# STM32L4x5 register map
File version: 1.8
CPU: CM4 r0p1, little endian, MPU, FPU, 4 interrupt priority bits
Registers are 32-bit, read-write, reset 0x0 unless marked. A register's access mark holds for its fields unless they carry their own. Offsets are from the block's base; [hi:lo] are bit positions; {n}, {i} and the like mark numbered series.

## AES — Advanced encryption standard hardware accelerator
Base 0x50060000
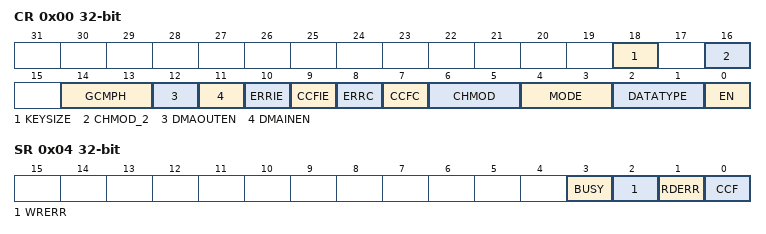
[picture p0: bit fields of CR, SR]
0x00 CR — control register
  [18] KEYSIZE — Key size selection
    0=AES128 (128); 1=AES256 (256)
  [16] CHMOD_2 — Chaining mode selection, bit [2]
    0=CHMOD (Mode as per CHMOD (ECB, CBC, CTR, GCM)); 1=CCM (Counter with CBC-MAC (CCM) - CHMOD must be 0 (ECB))
  [14:13] GCMPH — GCM or CCM phase selection
    0=Init phase; 1=Header phase; 2=Payload phase; 3=Final Phase
  [12] DMAOUTEN — Enable DMA management of data output phase
    0=Disable DMA Output; 1=Enabled DMA Output
  [11] DMAINEN — Enable DMA management of data input phase
    0=Disable DMA Input; 1=Enable DMA Input
  [10] ERRIE — Error interrupt enable
    0=Disabled (Disable (mask) error interrupt); 1=Enabled (Enable error interrupt)
  [9] CCFIE — CCF flag interrupt enable
    0=Disabled (Disable (mask) CCF interrupt); 1=Enabled (Enable CCF interrupt)
  [8] ERRC — Error clear
    on write: 1=Clear RDERR and WRERR flags
  [7] CCFC — Computation Complete Flag Clear
    on write: 1=Clear computation complete flag
  [6:5] CHMOD — AES chaining mode
    0=ECB (Electronic codebook (ECB) / Counter with CBC-MAC (CCM) if CHMOD2 is 1); 1=CBC (Cipher-block chaining (CBC)); 2=CTR (Counter mode (CTR)); 3=GCM (Galois counter mode (GCM) and Galois message authentication code (GMAC))
  [4:3] MODE — AES operating mode
    0=Mode 1: encryption; 1=Mode 2: key derivation (or key preparation for ECB/CBC decryption); 2=Mode 3: decryption; 3=Mode 4: key derivation then single decryption
  [2:1] DATATYPE — Data type selection (for data in and data out to/from the cryptographic block)
    0=None (Word); 1=Half-word (16-bit); 2=Byte (8-bit); 3=Bit
  [0] EN — AES enable
    0=Disabled (Disable AES); 1=Enabled (Enable AES)
0x04 SR ro — status register
  [3] BUSY
    0=Idle; 1=Busy
  [2] WRERR — Write error flag
    0=NoError (Write error not detected); 1=Error (Write error detected)
  [1] RDERR — Read error flag
    0=NoError (Read error not detected); 1=Error (Read error detected)
  [0] CCF — Computation complete flag
    0=Complete (Computation complete); 1=NotComplete (Computation not complete)
0x08 DINR — data input register
  [31:0] DIN — Data Input Register
0x0C DOUTR ro — data output register
  [31:0] DOUT — Data output register
0x10 KEYR0 — key register 0
  [31:0] KEY — Data Output Register (LSB key [31:0])
0x14 KEYR1 — key register 1
  [31:0] KEY — AES key register (key [63:32])
0x18 KEYR2 — key register 2
  [31:0] KEY — AES key register (key [95:64])
0x1C KEYR3 — key register 3
  [31:0] KEY — AES key register (MSB key [127:96])
0x20 IVR0 — initialization vector register 0
  [31:0] IVI — initialization vector register (LSB IVR [31:0])
0x24 IVR1 — initialization vector register 1
  [31:0] IVI — Initialization Vector Register (IVR [63:32])
0x28 IVR2 — initialization vector register 2
  [31:0] IVI — Initialization Vector Register (IVR [95:64])
0x2C IVR3 — initialization vector register 3
  [31:0] IVI — Initialization Vector Register (MSB IVR [127:96])
{0x20+4i} KEYR{i} (i=4..7) — key register {i}
  [31:0] KEY — Cryptographic key, bits [{32i+31}:{32i}]
{0x40+4i} SUSP{i}R (i=0..7) — suspend registers
  [31:0] SUSP — AES suspend

## TIM6 — Basic-timers
Base 0x40001000
Same registers: TIM7 0x40001400
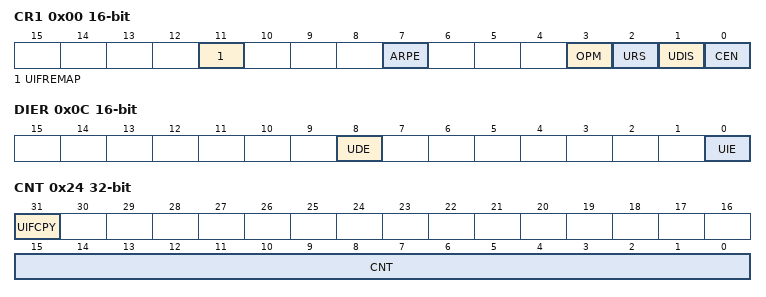
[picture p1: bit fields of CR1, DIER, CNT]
0x00 CR1 16-bit — control register 1
  [11] UIFREMAP — UIF status bit remapping
  [7] ARPE — Auto-reload preload enable
    0=Disabled (TIMx_APRR register is not buffered); 1=Enabled (TIMx_APRR register is buffered)
  [3] OPM — One-pulse mode
    0=Disabled (Counter is not stopped at update event); 1=Enabled (Counter stops counting at the next update event (clearing the CEN bit))
  [2] URS — Update request source
    0=AnyEvent (Any of counter overflow/underflow, setting UG, or update through slave mode, generates an update interrupt or DMA request); 1=CounterOnly (Only counter overflow/underflow generates an update interrupt or DMA request)
  [1] UDIS — Update disable
    0=Enabled (Update event enabled); 1=Disabled (Update event disabled)
  [0] CEN — Counter enable
    0=Disabled (Counter disabled); 1=Enabled (Counter enabled)
0x04 CR2 16-bit — control register 2
  [6:4] MMS — Master mode selection
    0=Reset (Use UG bit from TIMx_EGR register); 1=Enable (Use CNT bit from TIMx_CEN register); 2=Update (Use the update event)
0x0C DIER 16-bit — DMA/Interrupt enable register
  [8] UDE — Update DMA request enable
    0=Disabled (Update DMA request disabled); 1=Enabled (Update DMA request enabled)
  [0] UIE — Update interrupt enable
    0=Disabled (Update interrupt disabled); 1=Enabled (Update interrupt enabled)
0x10 SR 16-bit — status register
  [0] UIF write-0-clears — Update interrupt flag
    on read: 0=NoUpdateOccurred; 1=UpdatePending (Update interrupt pending) | on write: 0=Clear flag
0x14 EGR wo — event generation register
  [0] UG — Update generation
    1=Update (Re-initializes the timer counter and generates an update of the registers.)
0x24 CNT access per field — counter
  [31] UIFCPY ro — UIF Copy
  [15:0] CNT rw — Low counter value
0x24 CNT16 16-bit (alternate view of CNT) — 16-bit counter register
  [15:0] CNT — counter value
0x28 PSC 16-bit — prescaler
  [15:0] PSC — Prescaler value
0x2C ARR 16-bit reset 0xFFFF — auto-reload register
  [15:0] ARR — Prescaler value
